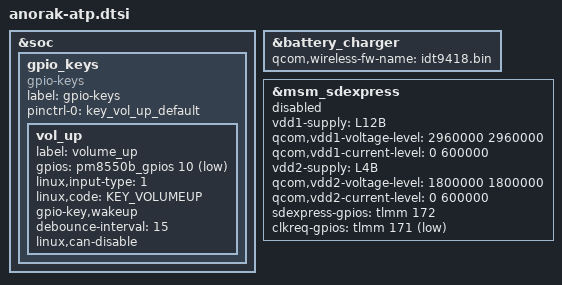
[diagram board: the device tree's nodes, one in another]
#include <dt-bindings/gpio/gpio.h>
#include <dt-bindings/input/input.h>

#include "anorak-pmic-overlay.dtsi"

&soc {
	gpio_keys {
		compatible = "gpio-keys";
		label = "gpio-keys";

		pinctrl-names = "default";
		pinctrl-0 = <&key_vol_up_default>;

		vol_up {
			label = "volume_up";
			gpios = <&pm8550b_gpios 10 GPIO_ACTIVE_LOW>;
			linux,input-type = <1>;
			linux,code = <KEY_VOLUMEUP>;
			gpio-key,wakeup;
			debounce-interval = <15>;
			linux,can-disable;
		};
	};
};

&battery_charger {
	qcom,wireless-fw-name = "idt9418.bin";
};

&msm_sdexpress {
	vdd1-supply = <&L12B>;
	qcom,vdd1-voltage-level = <2960000 2960000>;
	qcom,vdd1-current-level = <0 600000>;

	vdd2-supply = <&L4B>;
	qcom,vdd2-voltage-level = <1800000 1800000>;
	qcom,vdd2-current-level = <0 600000>;

	sdexpress-gpios = <&tlmm 172 0>;
	clkreq-gpios = <&tlmm 171 GPIO_ACTIVE_LOW>;

	status = "disabled";
};
